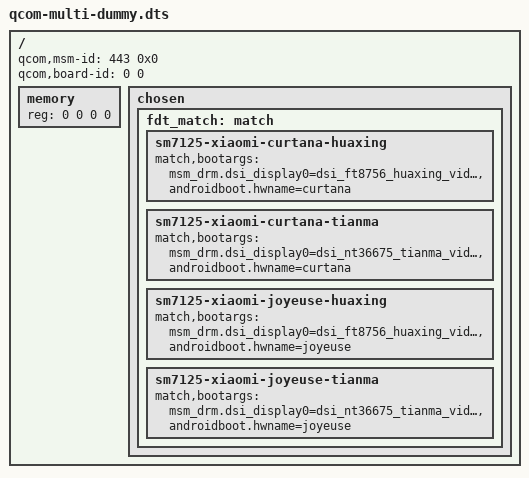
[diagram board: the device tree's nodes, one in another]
// SPDX-License-Identifier: GPL-2.0

/dts-v1/;

/ {
        qcom,msm-id = <443 0x0>;
        //qcom,board-id = <0x50022 1>;
	qcom,board-id = <0 0>;

	#address-cells = <2>;
	#size-cells = <2>;

	memory {
		/* We expect the bootloader to fill in the size */
		reg = <0 0 0 0>;
	};

	chosen {
		fdt_match: match { };
	};
};

&fdt_match {
	sm7125-xiaomi-curtana-huaxing {
		match,bootargs = "msm_drm.dsi_display0=dsi_ft8756_huaxing_vid_display", "androidboot.hwname=curtana";
	};

	sm7125-xiaomi-curtana-tianma {
		match,bootargs = "msm_drm.dsi_display0=dsi_nt36675_tianma_vid_display", "androidboot.hwname=curtana";
	};

	sm7125-xiaomi-joyeuse-huaxing {
		match,bootargs = "msm_drm.dsi_display0=dsi_ft8756_huaxing_vid_display", "androidboot.hwname=joyeuse";
	};

	sm7125-xiaomi-joyeuse-tianma {
		match,bootargs = "msm_drm.dsi_display0=dsi_nt36675_tianma_vid_display", "androidboot.hwname=joyeuse";
	};
};
